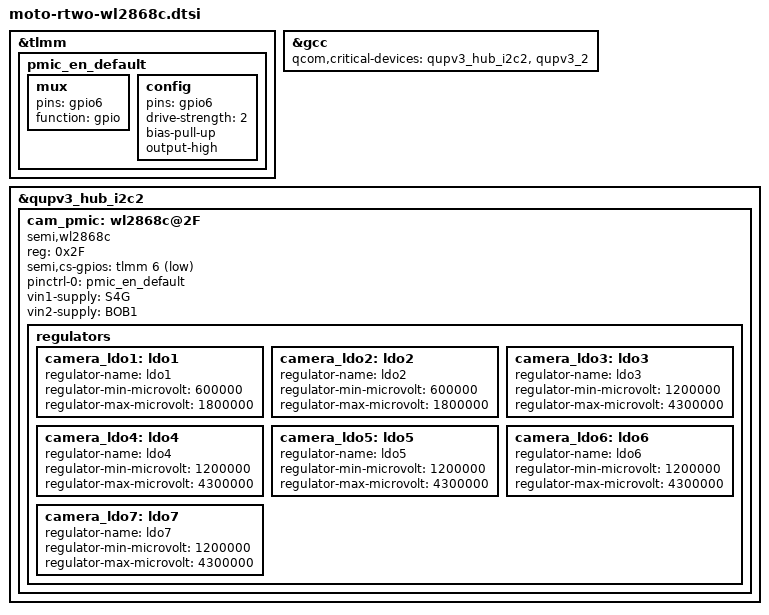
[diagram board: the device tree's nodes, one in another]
&tlmm{
	pmic_en_default: pmic_en_default {
		mux {
			pins = "gpio6";
			function = "gpio";
		};
		config {
			pins = "gpio6";
			drive-strength = <2>;
			bias-pull-up;
                        output-high;
		};
	};
};

/*
 * Each QUP device that's a parent to PMIC must be listed as a critical device
 * to GCC.
 */
&gcc {
	qcom,critical-devices = <&qupv3_hub_i2c2>, <&qupv3_2>;
};

&qupv3_hub_i2c2 {
	status = "ok";

	cam_pmic: wl2868c@2F{
		compatible = "semi,wl2868c";
		reg = <0x2F>;
		semi,cs-gpios = <&tlmm 6 1>;
		pinctrl-names = "default";
		pinctrl-0 = <&pmic_en_default>;
		vin1-supply = <&S4G>;
		vin2-supply = <&BOB1>;

		regulators {
			camera_ldo1: ldo1 {
				regulator-name = "ldo1";
				regulator-min-microvolt = <600000>;
				regulator-max-microvolt = <1800000>;
			};

			camera_ldo2: ldo2 {
				regulator-name = "ldo2";
				regulator-min-microvolt = <600000>;
				regulator-max-microvolt = <1800000>;
			};

			camera_ldo3: ldo3 {
				regulator-name = "ldo3";
				regulator-min-microvolt = <1200000>;
				regulator-max-microvolt = <4300000>;
			};

			camera_ldo4: ldo4 {
				regulator-name = "ldo4";
				regulator-min-microvolt = <1200000>;
				regulator-max-microvolt = <4300000>;
			};

			camera_ldo5: ldo5 {
				regulator-name = "ldo5";
				regulator-min-microvolt = <1200000>;
				regulator-max-microvolt = <4300000>;
			};

			camera_ldo6: ldo6 {
				regulator-name = "ldo6";
				regulator-min-microvolt = <1200000>;
				regulator-max-microvolt = <4300000>;
			};

			camera_ldo7: ldo7 {
				regulator-name = "ldo7";
				regulator-min-microvolt = <1200000>;
				regulator-max-microvolt = <4300000>;
			};
		};
	};
};
